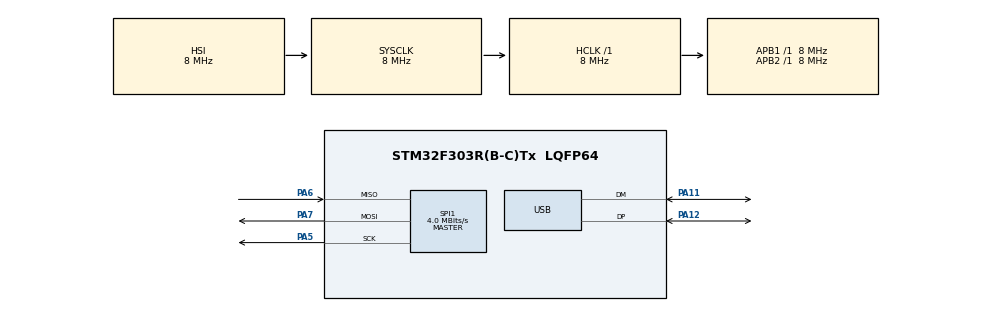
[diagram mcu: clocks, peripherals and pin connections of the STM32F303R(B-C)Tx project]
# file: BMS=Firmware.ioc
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Mcu.Family=STM32F3
Mcu.Name=STM32F303R(B-C)Tx
Mcu.Package=LQFP64
NVIC.PriorityGroup=NVIC_PRIORITYGROUP_4
NVIC.USB_LP_CAN_RX0_IRQn=true\:0\:0\:false\:false\:true\:false\:true\:true
PA11.Mode=Device
PA11.Signal=USB_DM
PA12.Mode=Device
PA12.Signal=USB_DP
PA13.Mode=Serial_Wire
PA13.Signal=SYS_JTMS-SWDIO
PA14.Mode=Serial_Wire
PA14.Signal=SYS_JTCK-SWCLK
PA5.Mode=Full_Duplex_Master
PA5.Signal=SPI1_SCK
PA6.Mode=Full_Duplex_Master
PA6.Signal=SPI1_MISO
PA7.Mode=Full_Duplex_Master
PA7.Signal=SPI1_MOSI
ProjectManager.HeapSize=0x200
ProjectManager.StackSize=0x400
ProjectManager.TargetToolchain=STM32CubeIDE
RCC.AHBFreq_Value=8000000
RCC.APB1Freq_Value=8000000
RCC.APB2Freq_Value=8000000
RCC.CortexFreq_Value=8000000
RCC.HSE_VALUE=8000000
RCC.HSI_VALUE=8000000
RCC.LSE_VALUE=32768
RCC.PLLSource=RCC_PLLSOURCE_HSI
RCC.PLLSourceVirtualString=RCC_PLLSOURCE_HSI
RCC.SYSCLKFreq_VALUE=8000000
SPI1.CalculateBaudRate=4.0 MBits/s
SPI1.Direction=SPI_DIRECTION_2LINES
SPI1.Mode=SPI_MODE_MASTER
SPI1.VirtualType=VM_MASTER
USB_DEVICE.CLASS_NAME_FS=CDC
USB_DEVICE.VirtualMode=Cdc
USB_DEVICE.VirtualModeFS=Cdc_FS
VP_USB_DEVICE_VS_USB_DEVICE_CDC_FS.Mode=CDC_FS
board=custom

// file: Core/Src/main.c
/* USER CODE BEGIN Header */
/**
  ******************************************************************************
  * @file           : main.c
  * @brief          : Main program body
  ******************************************************************************
  * @attention
  *
  * Copyright (c) 2026 STMicroelectronics.
  * All rights reserved.
  *
  * This software is licensed under terms that can be found in the LICENSE file
  * in the root directory of this software component.
  * If no LICENSE file comes with this software, it is provided AS-IS.
  *
  ******************************************************************************
  */
/* USER CODE END Header */
#include "main.h"
#include "usb_device.h"

/* USER CODE BEGIN Includes */
#include "sensors.h"
#include "usbd_cdc_if.h"
/* USER CODE END Includes */

SPI_HandleTypeDef hspi1;

/* USER CODE BEGIN PV */
ADC_HandleTypeDef hadc1;
I2C_HandleTypeDef hi2c1;
TIM_HandleTypeDef htim4;
/* USER CODE END PV */

void SystemClock_Config(void);
static void MX_GPIO_Init(void);
static void MX_SPI1_Init(void);
/* USER CODE BEGIN PFP */
int _write(int file, char *ptr, int len) {
    CDC_Transmit_FS((uint8_t*)ptr, len);
    return len;
}
/* USER CODE END PFP */

int main(void)
{

  /* MCU Configuration--------------------------------------------------------*/

  /* Reset of all peripherals, Initializes the Flash interface and the Systick. */
  HAL_Init();

  /* Configure the system clock */
  SystemClock_Config();

  /* Initialize all configured peripherals */
  MX_GPIO_Init();
  MX_SPI1_Init();
  MX_USB_DEVICE_Init();
  /* USER CODE BEGIN 2 */
  // ---------------------------------------------------------
  // BMS SENSOR INIT
  // ---------------------------------------------------------
  // Wait for USB enumeration briefly
  HAL_Delay(1000);
  printf("\r\n*** BMS DASHBOARD FIRMWARE BOOT ***\r\n");
  Sensors_Init();
  /* USER CODE END 2 */

  /* Infinite loop */
  while (1)
  {

    /* USER CODE BEGIN 3 */
    Sensors_Update_10Hz();
    HAL_Delay(100); // 10Hz loop
  }
  /* USER CODE END 3 */
}

void SystemClock_Config(void)
{
  RCC_OscInitTypeDef RCC_OscInitStruct = {0};
  RCC_ClkInitTypeDef RCC_ClkInitStruct = {0};
  RCC_PeriphCLKInitTypeDef PeriphClkInit = {0};

  /** Initializes the RCC Oscillators according to the specified parameters
  * in the RCC_OscInitTypeDef structure.
  */
  RCC_OscInitStruct.OscillatorType = RCC_OSCILLATORTYPE_HSI;
  RCC_OscInitStruct.HSIState = RCC_HSI_ON;
  RCC_OscInitStruct.HSICalibrationValue = RCC_HSICALIBRATION_DEFAULT;
  RCC_OscInitStruct.PLL.PLLState = RCC_PLL_ON;
  RCC_OscInitStruct.PLL.PLLSource = RCC_PLLSOURCE_HSI;
  RCC_OscInitStruct.PLL.PLLMUL = RCC_PLL_MUL2;
  if (HAL_RCC_OscConfig(&RCC_OscInitStruct) != HAL_OK)
  {
    Error_Handler();
  }

  /** Initializes the CPU, AHB and APB buses clocks
  */
  RCC_ClkInitStruct.ClockType = RCC_CLOCKTYPE_HCLK|RCC_CLOCKTYPE_SYSCLK
                              |RCC_CLOCKTYPE_PCLK1|RCC_CLOCKTYPE_PCLK2;
  RCC_ClkInitStruct.SYSCLKSource = RCC_SYSCLKSOURCE_HSI;
  RCC_ClkInitStruct.AHBCLKDivider = RCC_SYSCLK_DIV1;
  RCC_ClkInitStruct.APB1CLKDivider = RCC_HCLK_DIV1;
  RCC_ClkInitStruct.APB2CLKDivider = RCC_HCLK_DIV1;

  if (HAL_RCC_ClockConfig(&RCC_ClkInitStruct, FLASH_LATENCY_0) != HAL_OK)
  {
    Error_Handler();
  }
  PeriphClkInit.PeriphClockSelection = RCC_PERIPHCLK_USB;
  PeriphClkInit.USBClockSelection = RCC_USBCLKSOURCE_PLL;
  if (HAL_RCCEx_PeriphCLKConfig(&PeriphClkInit) != HAL_OK)
  {
    Error_Handler();
  }
}

static void MX_SPI1_Init(void)
{

  /* SPI1 parameter configuration*/
  hspi1.Instance = SPI1;
  hspi1.Init.Mode = SPI_MODE_MASTER;
  hspi1.Init.Direction = SPI_DIRECTION_2LINES;
  hspi1.Init.DataSize = SPI_DATASIZE_4BIT;
  hspi1.Init.CLKPolarity = SPI_POLARITY_LOW;
  hspi1.Init.CLKPhase = SPI_PHASE_1EDGE;
  hspi1.Init.NSS = SPI_NSS_SOFT;
  hspi1.Init.BaudRatePrescaler = SPI_BAUDRATEPRESCALER_2;
  hspi1.Init.FirstBit = SPI_FIRSTBIT_MSB;
  hspi1.Init.TIMode = SPI_TIMODE_DISABLE;
  hspi1.Init.CRCCalculation = SPI_CRCCALCULATION_DISABLE;
  hspi1.Init.CRCPolynomial = 7;
  hspi1.Init.CRCLength = SPI_CRC_LENGTH_DATASIZE;
  hspi1.Init.NSSPMode = SPI_NSS_PULSE_ENABLE;
  if (HAL_SPI_Init(&hspi1) != HAL_OK)
  {
    Error_Handler();
  }

}

static void MX_GPIO_Init(void)
{

  /* GPIO Ports Clock Enable */
  __HAL_RCC_GPIOA_CLK_ENABLE();

}

void Error_Handler(void)
{
  __disable_irq();
  while (1)
  {
  }
}
